# STM32WBxxx_CM4 register map
File version: 1.5
CPU: CM4 r0p1, little endian, MPU, FPU, 4 interrupt priority bits
Registers are 32-bit, read-write, reset 0x0 unless marked. A register's access mark holds for its fields unless they carry their own. Offsets are from the block's base; [hi:lo] are bit positions; 'fields as' and 'values as' point back to an identical list.

## TIM17 — General purpose timers
Base 0x40014800
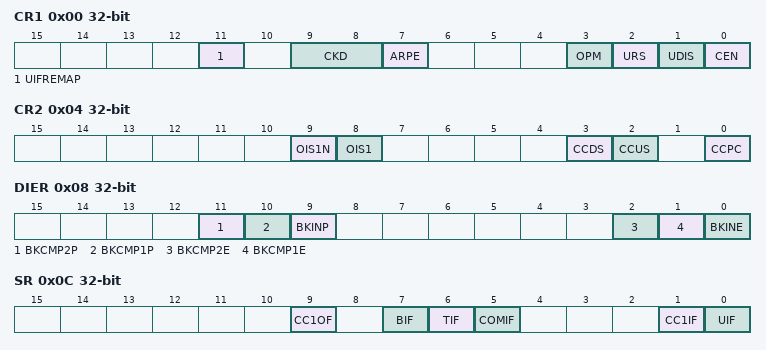
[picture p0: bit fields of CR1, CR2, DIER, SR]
0x00 CR1 — control register 1
  [11] UIFREMAP — UIF status bit remapping
  [9:8] CKD — Clock division
  [7] ARPE — Auto-reload preload enable
  [3] OPM — One-pulse mode
  [2] URS — Update request source
  [1] UDIS — Update disable
  [0] CEN — Counter enable
0x04 CR2 — control register 2
  [9] OIS1N — Output Idle state 1
  [8] OIS1 — Output Idle state 1
  [3] CCDS — Capture/compare DMA selection
  [2] CCUS — Capture/compare control update selection
  [0] CCPC — Capture/compare preloaded control
0x08 DIER — DMA/Interrupt enable register
  [11] BKCMP2P — BRK COMP2 input polarit
  [10] BKCMP1P — BRK COMP1 input polarity
  [9] BKINP — BRK BKIN input polarity
  [2] BKCMP2E — BRK COMP2 enable
  [1] BKCMP1E — BRK COMP1 enable
  [0] BKINE — BRK BKIN input enable
0x0C SR — status register
  [9] CC1OF — Capture/Compare 1 overcapture flag
  [7] BIF — Break interrupt flag
  [6] TIF — Trigger interrupt flag
  [5] COMIF — COM interrupt flag
  [1] CC1IF — Capture/compare 1 interrupt flag
  [0] UIF — Update interrupt flag
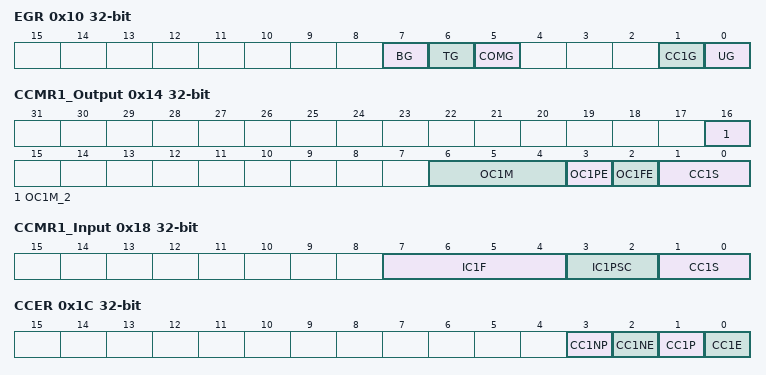
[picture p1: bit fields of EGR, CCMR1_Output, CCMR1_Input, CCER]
0x10 EGR wo — event generation register
  [7] BG — Break generation
  [6] TG — Trigger generation
  [5] COMG — Capture/Compare control update generation
  [1] CC1G — Capture/compare 1 generation
  [0] UG — Update generation
0x14 CCMR1_Output — capture/compare mode register (output mode)
  [16] OC1M_2 — Output Compare 1 mode
  [6:4] OC1M — Output Compare 1 mode
  [3] OC1PE — Output Compare 1 preload enable
  [2] OC1FE — Output Compare 1 fast enable
  [1:0] CC1S — Capture/Compare 1 selection
0x18 CCMR1_Input — capture/compare mode register 1 (input mode)
  [7:4] IC1F — Input capture 1 filter
  [3:2] IC1PSC — Input capture 1 prescaler
  [1:0] CC1S — Capture/Compare 1 selection
0x1C CCER — capture/compare enable register
  [3] CC1NP — Capture/Compare 1 output Polarity
  [2] CC1NE — Capture/Compare 1 complementary output enable
  [1] CC1P — Capture/Compare 1 output Polarity
  [0] CC1E — Capture/Compare 1 output enable
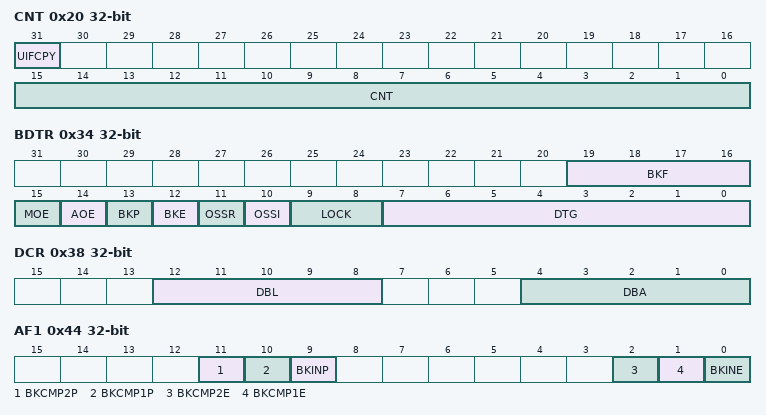
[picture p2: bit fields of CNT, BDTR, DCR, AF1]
0x20 CNT access per field — counter
  [31] UIFCPY ro — UIF Copy
  [15:0] CNT rw — counter value
0x24 PSC — prescaler
  [15:0] PSC — Prescaler value
0x28 ARR — auto-reload register
  [15:0] ARR — Auto-reload value
0x2C RCR — repetition counter register
  [7:0] REP — Repetition counter value
0x30 CCR1 — capture/compare register 1
  [15:0] CCR1 — Capture/Compare 1 value
0x34 BDTR — break and dead-time register
  [19:16] BKF — Break filter
  [15] MOE — Main output enable
  [14] AOE — Automatic output enable
  [13] BKP — Break polarity
  [12] BKE — Break enable
  [11] OSSR — Off-state selection for Run mode
  [10] OSSI — Off-state selection for Idle mode
  [9:8] LOCK — Lock configuration
  [7:0] DTG — Dead-time generator setup
0x38 DCR — DMA control register
  [12:8] DBL — DMA burst length
  [4:0] DBA — DMA base address
0x3C DMAR — DMA address for full transfer
  [15:0] DMAB — DMA register for burst accesses
0x40 OR — TIM16 option register 1
  [1:0] TI1_RMP — Input capture 1 remap
0x44 AF1 — TIM17 option register 1
  fields as DIER

## LPTIM1 — Low power timer
Base 0x40007C00
Same registers: LPTIM2 0x40009400
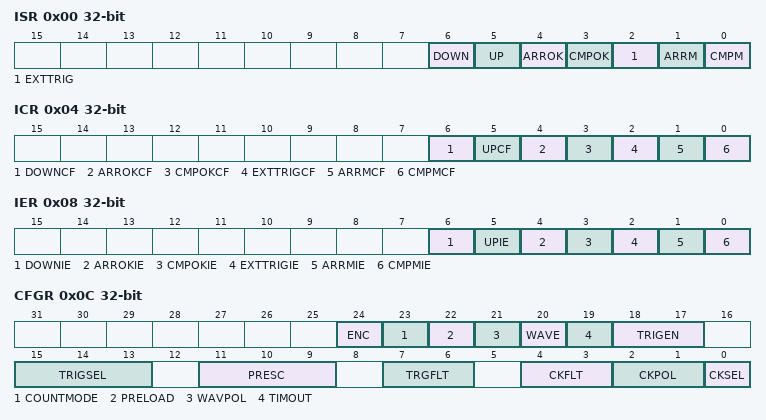
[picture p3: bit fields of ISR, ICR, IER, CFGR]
0x00 ISR ro — Interrupt and Status Register
  [6] DOWN — Counter direction change up to down
  [5] UP — Counter direction change down to up
  [4] ARROK — Autoreload register update OK
  [3] CMPOK — Compare register update OK
  [2] EXTTRIG — External trigger edge event
  [1] ARRM — Autoreload match
  [0] CMPM — Compare match
0x04 ICR wo — Interrupt Clear Register
  [6] DOWNCF — Direction change to down Clear Flag
  [5] UPCF — Direction change to UP Clear Flag
  [4] ARROKCF — Autoreload register update OK Clear Flag
  [3] CMPOKCF — Compare register update OK Clear Flag
  [2] EXTTRIGCF — External trigger valid edge Clear Flag
  [1] ARRMCF — Autoreload match Clear Flag
  [0] CMPMCF — compare match Clear Flag
0x08 IER — Interrupt Enable Register
  [6] DOWNIE — Direction change to down Interrupt Enable
  [5] UPIE — Direction change to UP Interrupt Enable
  [4] ARROKIE — Autoreload register update OK Interrupt Enable
  [3] CMPOKIE — Compare register update OK Interrupt Enable
  [2] EXTTRIGIE — External trigger valid edge Interrupt Enable
  [1] ARRMIE — Autoreload match Interrupt Enable
  [0] CMPMIE — Compare match Interrupt Enable
0x0C CFGR — Configuration Register
  [24] ENC — Encoder mode enable
  [23] COUNTMODE — counter mode enabled
  [22] PRELOAD — Registers update mode
  [21] WAVPOL — Waveform shape polarity
  [20] WAVE — Waveform shape
  [19] TIMOUT — Timeout enable
  [18:17] TRIGEN — Trigger enable and polarity
  [15:13] TRIGSEL — Trigger selector
  [11:9] PRESC — Clock prescaler
  [7:6] TRGFLT — Configurable digital filter for trigger
  [4:3] CKFLT — Configurable digital filter for external clock
  [2:1] CKPOL — Clock Polarity
  [0] CKSEL — Clock selector
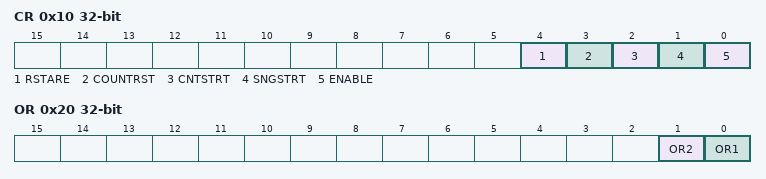
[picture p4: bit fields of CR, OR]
0x10 CR — Control Register
  [4] RSTARE — Reset after read enable
  [3] COUNTRST — Counter reset
  [2] CNTSTRT — Timer start in continuous mode
  [1] SNGSTRT — LPTIM start in single mode
  [0] ENABLE — LPTIM Enable
0x14 CMP — Compare Register
  [15:0] CMP — Compare value
0x18 ARR reset 0x1 — Autoreload Register
  [15:0] ARR — Auto reload value
0x1C CNT ro — Counter Register
  [15:0] CNT — Counter value
0x20 OR — Option Register
  [1] OR2 — Option register bit 2
  [0] OR1 — Option register bit 1
